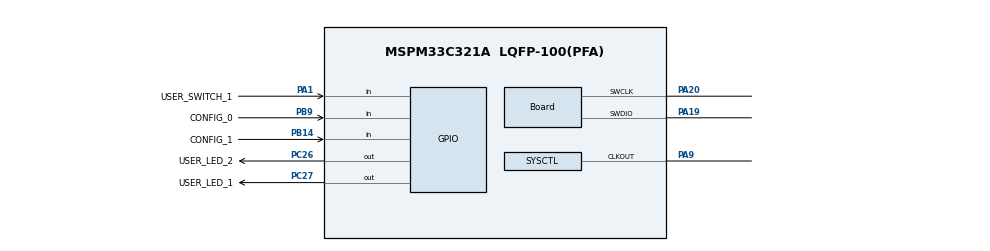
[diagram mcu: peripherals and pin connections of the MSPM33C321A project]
//@cliArgs --device "MSPM33C321A" --package "LQFP-100(PFA)" --part "Default"
//@v2CliArgs --device "MSPM33C321A" --package "LQFP-100(PFA)"
// @cliArgs --board /ti/boards/LP_MSPM33C321A --rtos nortos

/**
 * Import the modules used in this configuration.
 */
const GPIO   = scripting.addModule("/ti/driverlib/GPIO", {}, false);
const GPIO1  = GPIO.addInstance();
const GPIO2  = GPIO.addInstance();
const GPIO3  = GPIO.addInstance();
const SYSCTL = scripting.addModule("/ti/driverlib/SYSCTL");

/**
 * Write custom configuration values to the imported modules.
 */
GPIO1.$name                         = "GPIO_LEDS";
GPIO1.port                          = "PORTC";
GPIO1.associatedPins.create(2);
GPIO1.associatedPins[0].$name       = "USER_LED_1";
GPIO1.associatedPins[0].pin.$assign = "PC27";
GPIO1.associatedPins[1].$name       = "USER_LED_2";
GPIO1.associatedPins[1].pin.$assign = "PC26";

const Board                       = scripting.addModule("/ti/driverlib/Board", {}, false);
Board.peripheral.$assign          = "DEBUGSS";
Board.peripheral.swclkPin.$assign = "PA20";
Board.peripheral.swdioPin.$assign = "PA19";

GPIO2.$name                              = "GPIO_INPUT";
GPIO2.port                               = "PORTB";
GPIO2.associatedPins.create(2);
GPIO2.associatedPins[0].$name            = "CONFIG_0";
GPIO2.associatedPins[0].direction        = "INPUT";
GPIO2.associatedPins[0].internalResistor = "PULL_DOWN";
GPIO2.associatedPins[0].pin.$assign      = "PB9";
GPIO2.associatedPins[1].$name            = "CONFIG_1";
GPIO2.associatedPins[1].direction        = "INPUT";
GPIO2.associatedPins[1].internalResistor = "PULL_DOWN";
GPIO2.associatedPins[1].pin.$assign      = "PB14";

GPIO3.$name                              = "GPIO_SWITCH";
GPIO3.associatedPins[0].$name            = "USER_SWITCH_1";
GPIO3.associatedPins[0].direction        = "INPUT";
GPIO3.associatedPins[0].internalResistor = "PULL_DOWN";
GPIO3.associatedPins[0].wakeupLogic      = "ON_1";
GPIO3.associatedPins[0].pin.$assign      = "PA1";

SYSCTL.forceDefaultClkConfig        = true;
SYSCTL.enableEXCLK                  = true;
SYSCTL.fccTrigSrc                   = "LFCLK";
SYSCTL.fccClkSrc                    = "SYSOSC";
SYSCTL.fccPeriods                   = "02";
SYSCTL.HFCLKSource                  = "HFXT";
SYSCTL.HFCLK_Freq                   = 40000000;
SYSCTL.HFXTStartup                  = 10;
SYSCTL.HFCLKMonitor                 = true;
SYSCTL.HSCLKSource                  = "HFCLK";
SYSCTL.EXCLKSource                  = "ULPCLK";
SYSCTL.EXCLKDivider                 = "16";
SYSCTL.peripheral.$assign           = "SYSCTL";
SYSCTL.peripheral.clkOutPin.$assign = "PA9";

const ProjectConfig              = scripting.addModule("/ti/project_config/ProjectConfig", {}, false);
ProjectConfig.migrationCondition = true;
